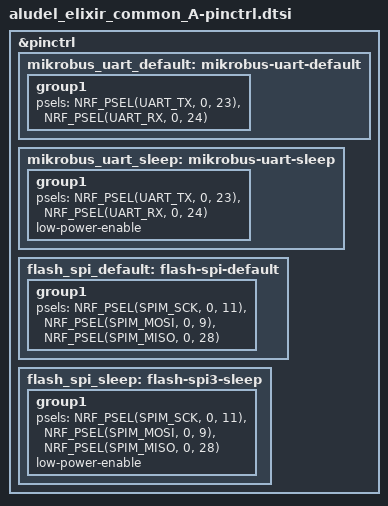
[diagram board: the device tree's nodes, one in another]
/*
 * Copyright (c) 2024 Golioth, Inc.
 *
 * SPDX-License-Identifier: Apache-2.0
 */

&pinctrl {
	/* UART pins connected to the mikroBUS headers */
	mikrobus_uart_default: mikrobus-uart-default {
		group1 {
			psels = <NRF_PSEL(UART_TX, 0, 23)>,
				<NRF_PSEL(UART_RX, 0, 24)>;
		};
	};

	mikrobus_uart_sleep: mikrobus-uart-sleep {
		group1 {
			psels = <NRF_PSEL(UART_TX, 0, 23)>,
				<NRF_PSEL(UART_RX, 0, 24)>;
			low-power-enable;
		};
	};

	/* SPI pins connected to external NOR flash */
	flash_spi_default: flash-spi-default {
		group1 {
			psels = <NRF_PSEL(SPIM_SCK, 0, 11)>,
			        <NRF_PSEL(SPIM_MOSI, 0, 9)>,
			        <NRF_PSEL(SPIM_MISO, 0, 28)>;
		};
	};

	flash_spi_sleep: flash-spi3-sleep {
		group1 {
			psels = <NRF_PSEL(SPIM_SCK, 0, 11)>,
			        <NRF_PSEL(SPIM_MOSI, 0, 9)>,
			        <NRF_PSEL(SPIM_MISO, 0, 28)>;
			low-power-enable;
		};
	};
};
